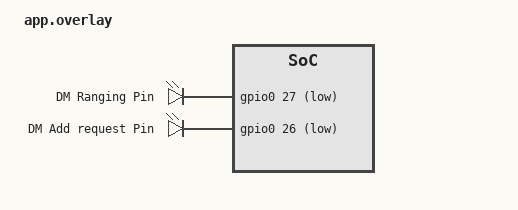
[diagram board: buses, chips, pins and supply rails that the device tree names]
/*
 * Copyright (c) 2023 Nordic Semiconductor ASA
 *
 * SPDX-License-Identifier: LicenseRef-Nordic-5-Clause
 */

/ {
	/* The timer instance to use. */
	chosen {
		ncs,dm-timer = &timer2;
	};

	/* The selected pins will be used by Distance Measurement module for debug purposes. */
	dm_gpio {
		compatible = "gpio-leds";
		dm_ranging: dm-ranging {
			gpios = <&gpio0 27 GPIO_ACTIVE_LOW>;
			label = "DM Ranging Pin";
		};
		dm_add_request: dm-add-request {
			gpios = <&gpio0 26 GPIO_ACTIVE_LOW>;
			label = "DM Add request Pin";
		};
	};
};
